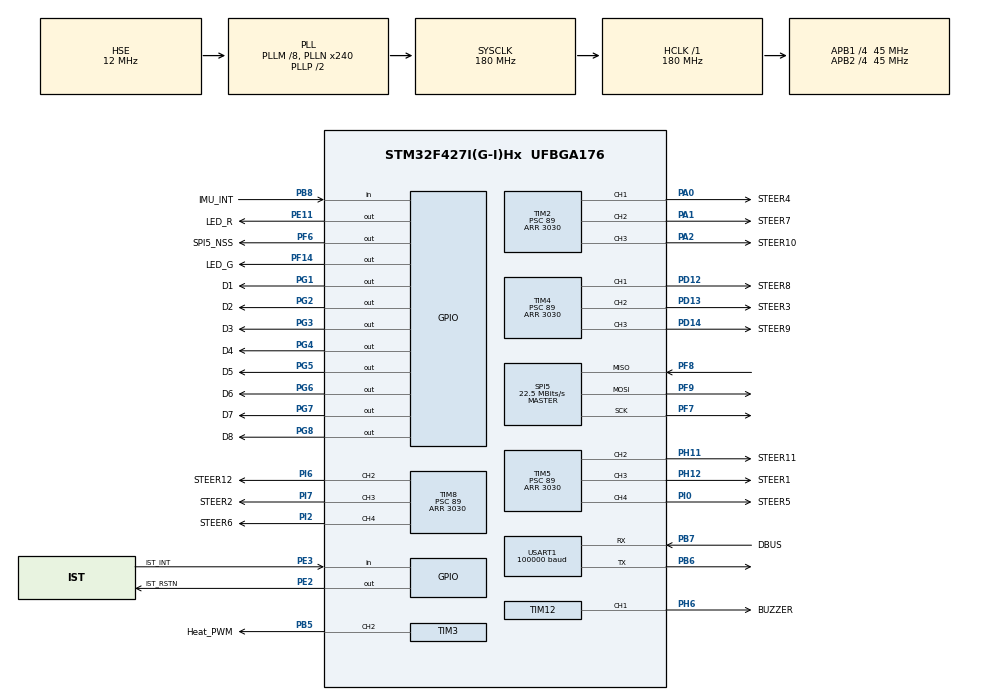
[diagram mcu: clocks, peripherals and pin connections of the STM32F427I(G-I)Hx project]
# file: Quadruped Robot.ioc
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Dma.Request0=USART1_RX
Dma.USART1_RX.0.Direction=DMA_PERIPH_TO_MEMORY
Dma.USART1_RX.0.FIFOMode=DMA_FIFOMODE_DISABLE
Dma.USART1_RX.0.Instance=DMA2_Stream2
Dma.USART1_RX.0.MemDataAlignment=DMA_MDATAALIGN_BYTE
Dma.USART1_RX.0.MemInc=DMA_MINC_ENABLE
Dma.USART1_RX.0.Mode=DMA_NORMAL
Dma.USART1_RX.0.PeriphDataAlignment=DMA_PDATAALIGN_BYTE
Dma.USART1_RX.0.PeriphInc=DMA_PINC_DISABLE
Dma.USART1_RX.0.Priority=DMA_PRIORITY_LOW
FREERTOS.Tasks01=defaultTask,0,128,StartDefaultTask,Default,NULL,Dynamic,NULL,NULL;InitTask,-3,128,StartInitTask,As weak,NULL,Dynamic,NULL,NULL
Mcu.Family=STM32F4
Mcu.Name=STM32F427I(G-I)Hx
Mcu.Package=UFBGA176
NVIC.DMA2_Stream2_IRQn=true\:5\:0\:false\:false\:true\:true\:false
NVIC.PriorityGroup=NVIC_PRIORITYGROUP_4
NVIC.TIM1_UP_TIM10_IRQn=true\:0\:0\:false\:false\:true\:false\:false
NVIC.TimeBase=TIM1_UP_TIM10_IRQn
NVIC.TimeBaseIP=TIM1
NVIC.USART1_IRQn=true\:5\:0\:false\:false\:true\:true\:true
PA0/WKUP.GPIO_Label=STEER4
PA0/WKUP.Signal=S_TIM2_CH1_ETR
PA1.GPIO_Label=STEER7
PA1.Signal=S_TIM2_CH2
PA13.Mode=Serial_Wire
PA13.Signal=SYS_JTMS-SWDIO
PA14.Mode=Serial_Wire
PA14.Signal=SYS_JTCK-SWCLK
PA2.GPIO_Label=STEER10
PA2.Signal=S_TIM2_CH3
PB5.GPIO_Label=Heat_PWM
PB5.Signal=S_TIM3_CH2
PB6.Mode=Asynchronous
PB6.Signal=USART1_TX
PB7.GPIO_Label=DBUS
PB7.Mode=Asynchronous
PB7.Signal=USART1_RX
PB8.GPIO_Label=IMU_INT
PB8.Signal=GPIO_Input
PD12.GPIO_Label=STEER8
PD12.Signal=S_TIM4_CH1
PD13.GPIO_Label=STEER3
PD13.Signal=S_TIM4_CH2
PD14.GPIO_Label=STEER9
PD14.Signal=S_TIM4_CH3
PE11.GPIO_Label=LED_R
PE11.PinState=GPIO_PIN_SET
PE11.Signal=GPIO_Output
PE2.GPIO_Label=IST_RSTN
PE2.Signal=GPIO_Output
PE3.GPIO_Label=IST_INT
PE3.Signal=GPIO_Input
PF14.GPIO_Label=LED_G
PF14.PinState=GPIO_PIN_SET
PF14.Signal=GPIO_Output
PF6.GPIO_Label=SPI5_NSS
PF6.Signal=GPIO_Output
PF7.Mode=Full_Duplex_Master
PF7.Signal=SPI5_SCK
PF8.Mode=Full_Duplex_Master
PF8.Signal=SPI5_MISO
PF9.Mode=Full_Duplex_Master
PF9.Signal=SPI5_MOSI
PG1.GPIO_Label=D1
PG1.PinState=GPIO_PIN_SET
PG1.Signal=GPIO_Output
PG2.GPIO_Label=D2
PG2.PinState=GPIO_PIN_SET
PG2.Signal=GPIO_Output
PG3.GPIO_Label=D3
PG3.PinState=GPIO_PIN_SET
PG3.Signal=GPIO_Output
PG4.GPIO_Label=D4
PG4.PinState=GPIO_PIN_SET
PG4.Signal=GPIO_Output
PG5.GPIO_Label=D5
PG5.PinState=GPIO_PIN_SET
PG5.Signal=GPIO_Output
PG6.GPIO_Label=D6
PG6.PinState=GPIO_PIN_SET
PG6.Signal=GPIO_Output
PG7.GPIO_Label=D7
PG7.PinState=GPIO_PIN_SET
PG7.Signal=GPIO_Output
PG8.GPIO_Label=D8
PG8.PinState=GPIO_PIN_SET
PG8.Signal=GPIO_Output
PH0/OSC_IN.Mode=HSE-External-Oscillator
PH0/OSC_IN.Signal=RCC_OSC_IN
PH1/OSC_OUT.Mode=HSE-External-Oscillator
PH1/OSC_OUT.Signal=RCC_OSC_OUT
PH11.GPIO_Label=STEER11
PH11.Signal=S_TIM5_CH2
PH12.GPIO_Label=STEER1
PH12.Signal=S_TIM5_CH3
PH6.GPIO_Label=BUZZER
PH6.Signal=S_TIM12_CH1
PI0.GPIO_Label=STEER5
PI0.Signal=S_TIM5_CH4
PI2.GPIO_Label=STEER6
PI2.Signal=S_TIM8_CH4
PI6.GPIO_Label=STEER12
PI6.Signal=S_TIM8_CH2
PI7.GPIO_Label=STEER2
PI7.Signal=S_TIM8_CH3
ProjectManager.HeapSize=0x200
ProjectManager.StackSize=0x400
ProjectManager.TargetToolchain=MDK-ARM V5
RCC.48MHZClocksFreq_Value=90000000
RCC.AHBFreq_Value=180000000
RCC.APB1CLKDivider=RCC_HCLK_DIV4
RCC.APB1Freq_Value=45000000
RCC.APB1TimFreq_Value=90000000
RCC.APB2CLKDivider=RCC_HCLK_DIV4
RCC.APB2Freq_Value=45000000
RCC.APB2TimFreq_Value=90000000
RCC.CortexFreq_Value=180000000
RCC.HCLKFreq_Value=180000000
RCC.HSE_VALUE=12000000
RCC.HSI_VALUE=16000000
RCC.LSE_VALUE=32768
RCC.PLLM=8
RCC.PLLN=240
RCC.PLLSourceVirtual=RCC_PLLSOURCE_HSE
RCC.SYSCLKFreq_VALUE=180000000
RCC.SYSCLKSource=RCC_SYSCLKSOURCE_PLLCLK
RCC.VCOOutputFreq_Value=360000000
SH.S_TIM12_CH1.0=TIM12_CH1,PWM Generation1 CH1
SH.S_TIM2_CH1_ETR.0=TIM2_CH1,PWM Generation1 CH1
SH.S_TIM2_CH2.0=TIM2_CH2,PWM Generation2 CH2
SH.S_TIM2_CH3.0=TIM2_CH3,PWM Generation3 CH3
SH.S_TIM3_CH2.0=TIM3_CH2,PWM Generation2 CH2
SH.S_TIM4_CH1.0=TIM4_CH1,PWM Generation1 CH1
SH.S_TIM4_CH2.0=TIM4_CH2,PWM Generation2 CH2
SH.S_TIM4_CH3.0=TIM4_CH3,PWM Generation3 CH3
SH.S_TIM5_CH2.0=TIM5_CH2,PWM Generation2 CH2
SH.S_TIM5_CH3.0=TIM5_CH3,PWM Generation3 CH3
SH.S_TIM5_CH4.0=TIM5_CH4,PWM Generation4 CH4
SH.S_TIM8_CH2.0=TIM8_CH2,PWM Generation2 CH2
SH.S_TIM8_CH3.0=TIM8_CH3,PWM Generation3 CH3
SH.S_TIM8_CH4.0=TIM8_CH4,PWM Generation4 CH4
SPI5.BaudRatePrescaler=SPI_BAUDRATEPRESCALER_2
SPI5.CalculateBaudRate=22.5 MBits/s
SPI5.Direction=SPI_DIRECTION_2LINES
SPI5.Mode=SPI_MODE_MASTER
SPI5.VirtualType=VM_MASTER
TIM12.Channel-PWM\ Generation1\ CH1=TIM_CHANNEL_1
TIM12.Prescaler=89
TIM2.Channel-PWM\ Generation1\ CH1=TIM_CHANNEL_1
TIM2.Channel-PWM\ Generation2\ CH2=TIM_CHANNEL_2
TIM2.Channel-PWM\ Generation3\ CH3=TIM_CHANNEL_3
TIM2.Period=3030
TIM2.Prescaler=89
TIM3.Channel-PWM\ Generation2\ CH2=TIM_CHANNEL_2
TIM3.Period=999
TIM3.Prescaler=89
TIM4.Channel-PWM\ Generation1\ CH1=TIM_CHANNEL_1
TIM4.Channel-PWM\ Generation2\ CH2=TIM_CHANNEL_2
TIM4.Channel-PWM\ Generation3\ CH3=TIM_CHANNEL_3
TIM4.Period=3030
TIM4.Prescaler=89
TIM5.Channel-PWM\ Generation2\ CH2=TIM_CHANNEL_2
TIM5.Channel-PWM\ Generation3\ CH3=TIM_CHANNEL_3
TIM5.Channel-PWM\ Generation4\ CH4=TIM_CHANNEL_4
TIM5.Period=3030
TIM5.Prescaler=89
TIM8.Channel-PWM\ Generation2\ CH2=TIM_CHANNEL_2
TIM8.Channel-PWM\ Generation3\ CH3=TIM_CHANNEL_3
TIM8.Channel-PWM\ Generation4\ CH4=TIM_CHANNEL_4
TIM8.Period=3030
TIM8.Prescaler=89
USART1.BaudRate=100000
USART1.Parity=PARITY_EVEN
USART1.VirtualMode=VM_ASYNC
USART1.WordLength=WORDLENGTH_9B
VP_FREERTOS_VS_ENABLE.Mode=Enabled
VP_SYS_VS_tim1.Mode=TIM1
board=custom

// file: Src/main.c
/**
  ******************************************************************************
  * @file           : main.c
  * @brief          : Main program body
  ******************************************************************************
  * This notice applies to any and all portions of this file
  * that are not between comment pairs USER CODE BEGIN and
  * USER CODE END. Other portions of this file, whether
  * inserted by the user or by software development tools
  * are owned by their respective copyright owners.
  *
  * Copyright (c) 2020 STMicroelectronics International N.V.
  * All rights reserved.
  *
  * Redistribution and use in source and binary forms, with or without
  * modification, are permitted, provided that the following conditions are met:
  *
  * 1. Redistribution of source code must retain the above copyright notice,
  *    this list of conditions and the following disclaimer.
  * 2. Redistributions in binary form must reproduce the above copyright notice,
  *    this list of conditions and the following disclaimer in the documentation
  *    and/or other materials provided with the distribution.
  * 3. Neither the name of STMicroelectronics nor the names of other
  *    contributors to this software may be used to endorse or promote products
  *    derived from this software without specific written permission.
  * 4. This software, including modifications and/or derivative works of this
  *    software, must execute solely and exclusively on microcontroller or
  *    microprocessor devices manufactured by or for STMicroelectronics.
  * 5. Redistribution and use of this software other than as permitted under
  *    this license is void and will automatically terminate your rights under
  *    this license.
  *
  * THIS SOFTWARE IS PROVIDED BY STMICROELECTRONICS AND CONTRIBUTORS "AS IS"
  * AND ANY EXPRESS, IMPLIED OR STATUTORY WARRANTIES, INCLUDING, BUT NOT
  * LIMITED TO, THE IMPLIED WARRANTIES OF MERCHANTABILITY, FITNESS FOR A
  * PARTICULAR PURPOSE AND NON-INFRINGEMENT OF THIRD PARTY INTELLECTUAL PROPERTY
  * RIGHTS ARE DISCLAIMED TO THE FULLEST EXTENT PERMITTED BY LAW. IN NO EVENT
  * SHALL STMICROELECTRONICS OR CONTRIBUTORS BE LIABLE FOR ANY DIRECT, INDIRECT,
  * INCIDENTAL, SPECIAL, EXEMPLARY, OR CONSEQUENTIAL DAMAGES (INCLUDING, BUT NOT
  * LIMITED TO, PROCUREMENT OF SUBSTITUTE GOODS OR SERVICES; LOSS OF USE, DATA,
  * OR PROFITS; OR BUSINESS INTERRUPTION) HOWEVER CAUSED AND ON ANY THEORY OF
  * LIABILITY, WHETHER IN CONTRACT, STRICT LIABILITY, OR TORT (INCLUDING
  * NEGLIGENCE OR OTHERWISE) ARISING IN ANY WAY OUT OF THE USE OF THIS SOFTWARE,
  * EVEN IF ADVISED OF THE POSSIBILITY OF SUCH DAMAGE.
  *
  ******************************************************************************
  */
#include "main.h"
#include "stm32f4xx_hal.h"
#include "cmsis_os.h"
#include "dma.h"
#include "spi.h"
#include "tim.h"
#include "usart.h"
#include "gpio.h"

/* USER CODE BEGIN PV */
/* Private variables ---------------------------------------------------------*/

/* USER CODE END PV */

void SystemClock_Config(void);
void MX_FREERTOS_Init(void);

/* USER CODE BEGIN PFP */
/* Private function prototypes -----------------------------------------------*/

/* USER CODE END PFP */

int main(void)
{

  /* MCU Configuration----------------------------------------------------------*/

  /* Reset of all peripherals, Initializes the Flash interface and the Systick. */
  HAL_Init();

  /* Configure the system clock */
  SystemClock_Config();

  /* Initialize all configured peripherals */
  MX_GPIO_Init();
  MX_DMA_Init();
  MX_SPI5_Init();
  MX_TIM2_Init();
  MX_TIM3_Init();
  MX_TIM4_Init();
  MX_TIM5_Init();
  MX_TIM8_Init();
  MX_TIM12_Init();
  MX_USART1_UART_Init();
  /* USER CODE BEGIN 2 */
	HAL_TIM_PWM_Init(&htim2);
	HAL_TIM_PWM_Init(&htim3);
	HAL_TIM_PWM_Init(&htim4);
	HAL_TIM_PWM_Init(&htim5);
	HAL_TIM_PWM_Init(&htim8);
  /* USER CODE END 2 */

  /* Call init function for freertos objects (in freertos.c) */
  MX_FREERTOS_Init();

  /* Start scheduler */
  osKernelStart();

  /* We should never get here as control is now taken by the scheduler */

  /* Infinite loop */
  while (1)
  {

  }

}

void SystemClock_Config(void)
{

  RCC_OscInitTypeDef RCC_OscInitStruct;
  RCC_ClkInitTypeDef RCC_ClkInitStruct;

    /**Configure the main internal regulator output voltage
    */
  __HAL_RCC_PWR_CLK_ENABLE();

  __HAL_PWR_VOLTAGESCALING_CONFIG(PWR_REGULATOR_VOLTAGE_SCALE1);

    /**Initializes the CPU, AHB and APB busses clocks
    */
  RCC_OscInitStruct.OscillatorType = RCC_OSCILLATORTYPE_HSE;
  RCC_OscInitStruct.HSEState = RCC_HSE_ON;
  RCC_OscInitStruct.PLL.PLLState = RCC_PLL_ON;
  RCC_OscInitStruct.PLL.PLLSource = RCC_PLLSOURCE_HSE;
  RCC_OscInitStruct.PLL.PLLM = 8;
  RCC_OscInitStruct.PLL.PLLN = 240;
  RCC_OscInitStruct.PLL.PLLP = RCC_PLLP_DIV2;
  RCC_OscInitStruct.PLL.PLLQ = 4;
  if (HAL_RCC_OscConfig(&RCC_OscInitStruct) != HAL_OK)
  {
    _Error_Handler(__FILE__, __LINE__);
  }

    /**Activate the Over-Drive mode
    */
  if (HAL_PWREx_EnableOverDrive() != HAL_OK)
  {
    _Error_Handler(__FILE__, __LINE__);
  }

    /**Initializes the CPU, AHB and APB busses clocks
    */
  RCC_ClkInitStruct.ClockType = RCC_CLOCKTYPE_HCLK|RCC_CLOCKTYPE_SYSCLK
                              |RCC_CLOCKTYPE_PCLK1|RCC_CLOCKTYPE_PCLK2;
  RCC_ClkInitStruct.SYSCLKSource = RCC_SYSCLKSOURCE_PLLCLK;
  RCC_ClkInitStruct.AHBCLKDivider = RCC_SYSCLK_DIV1;
  RCC_ClkInitStruct.APB1CLKDivider = RCC_HCLK_DIV4;
  RCC_ClkInitStruct.APB2CLKDivider = RCC_HCLK_DIV4;

  if (HAL_RCC_ClockConfig(&RCC_ClkInitStruct, FLASH_LATENCY_5) != HAL_OK)
  {
    _Error_Handler(__FILE__, __LINE__);
  }

    /**Configure the Systick interrupt time
    */
  HAL_SYSTICK_Config(HAL_RCC_GetHCLKFreq()/1000);

    /**Configure the Systick
    */
  HAL_SYSTICK_CLKSourceConfig(SYSTICK_CLKSOURCE_HCLK);

  /* SysTick_IRQn interrupt configuration */
  HAL_NVIC_SetPriority(SysTick_IRQn, 15, 0);
}

void HAL_TIM_PeriodElapsedCallback(TIM_HandleTypeDef *htim)
{
  if (htim->Instance == TIM1) {
    HAL_IncTick();
  }
}

void _Error_Handler(char *file, int line)
{
  while(1)
  {
  }
}

/************************ (C) COPYRIGHT STMicroelectronics *****END OF FILE****/

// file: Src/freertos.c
/* USER CODE BEGIN Header */
/**
  ******************************************************************************
  * File Name          : freertos.c
  * Description        : Code for freertos applications
  ******************************************************************************
  * This notice applies to any and all portions of this file
  * that are not between comment pairs USER CODE BEGIN and
  * USER CODE END. Other portions of this file, whether
  * inserted by the user or by software development tools
  * are owned by their respective copyright owners.
  *
  * Copyright (c) 2020 STMicroelectronics International N.V.
  * All rights reserved.
  *
  * Redistribution and use in source and binary forms, with or without
  * modification, are permitted, provided that the following conditions are met:
  *
  * 1. Redistribution of source code must retain the above copyright notice,
  *    this list of conditions and the following disclaimer.
  * 2. Redistributions in binary form must reproduce the above copyright notice,
  *    this list of conditions and the following disclaimer in the documentation
  *    and/or other materials provided with the distribution.
  * 3. Neither the name of STMicroelectronics nor the names of other
  *    contributors to this software may be used to endorse or promote products
  *    derived from this software without specific written permission.
  * 4. This software, including modifications and/or derivative works of this
  *    software, must execute solely and exclusively on microcontroller or
  *    microprocessor devices manufactured by or for STMicroelectronics.
  * 5. Redistribution and use of this software other than as permitted under
  *    this license is void and will automatically terminate your rights under
  *    this license.
  *
  * THIS SOFTWARE IS PROVIDED BY STMICROELECTRONICS AND CONTRIBUTORS "AS IS"
  * AND ANY EXPRESS, IMPLIED OR STATUTORY WARRANTIES, INCLUDING, BUT NOT
  * LIMITED TO, THE IMPLIED WARRANTIES OF MERCHANTABILITY, FITNESS FOR A
  * PARTICULAR PURPOSE AND NON-INFRINGEMENT OF THIRD PARTY INTELLECTUAL PROPERTY
  * RIGHTS ARE DISCLAIMED TO THE FULLEST EXTENT PERMITTED BY LAW. IN NO EVENT
  * SHALL STMICROELECTRONICS OR CONTRIBUTORS BE LIABLE FOR ANY DIRECT, INDIRECT,
  * INCIDENTAL, SPECIAL, EXEMPLARY, OR CONSEQUENTIAL DAMAGES (INCLUDING, BUT NOT
  * LIMITED TO, PROCUREMENT OF SUBSTITUTE GOODS OR SERVICES; LOSS OF USE, DATA,
  * OR PROFITS; OR BUSINESS INTERRUPTION) HOWEVER CAUSED AND ON ANY THEORY OF
  * LIABILITY, WHETHER IN CONTRACT, STRICT LIABILITY, OR TORT (INCLUDING
  * NEGLIGENCE OR OTHERWISE) ARISING IN ANY WAY OUT OF THE USE OF THIS SOFTWARE,
  * EVEN IF ADVISED OF THE POSSIBILITY OF SUCH DAMAGE.
  *
  ******************************************************************************
  */
/* USER CODE END Header */

#include "FreeRTOS.h"
#include "task.h"
#include "main.h"
#include "cmsis_os.h"

osThreadId defaultTaskHandle;
osThreadId InitTaskHandle;

void StartDefaultTask(void const * argument);
void StartInitTask(void const * argument);

void MX_FREERTOS_Init(void); /* (MISRA C 2004 rule 8.1) */

void MX_FREERTOS_Init(void) {

  /* Create the thread(s) */
  /* definition and creation of defaultTask */
  osThreadDef(defaultTask, StartDefaultTask, osPriorityNormal, 0, 128);
  defaultTaskHandle = osThreadCreate(osThread(defaultTask), NULL);

  /* definition and creation of InitTask */
  osThreadDef(InitTask, StartInitTask, osPriorityIdle, 0, 128);
  InitTaskHandle = osThreadCreate(osThread(InitTask), NULL);

}

void StartDefaultTask(void const * argument)
{

  for(;;)
  {
    osDelay(1);
  }
}

__weak void StartInitTask(void const * argument)
{
  for(;;)
  {
    osDelay(1);
  }
}

/************************ (C) COPYRIGHT STMicroelectronics *****END OF FILE****/
